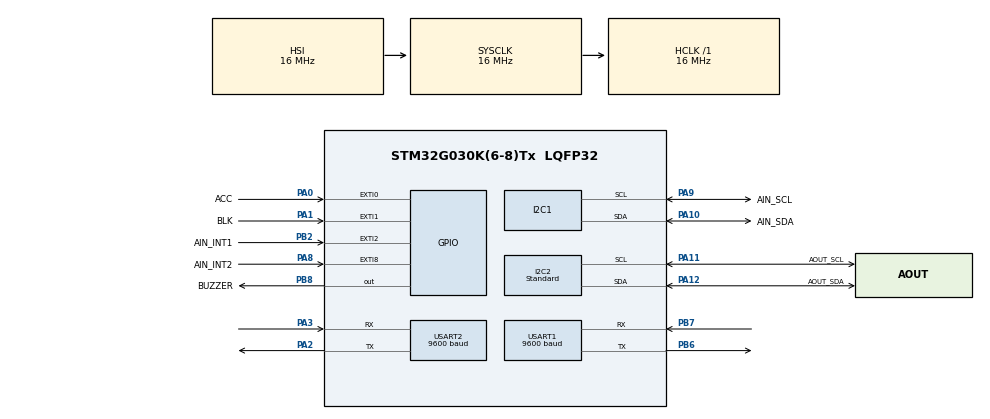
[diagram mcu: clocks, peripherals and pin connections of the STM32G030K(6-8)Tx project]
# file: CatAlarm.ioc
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I2C1.Speed=100
I2C2.I2C_Speed_Mode=I2C_Standard
Mcu.Family=STM32G0
Mcu.Name=STM32G030K(6-8)Tx
Mcu.Package=LQFP32
NVIC.EXTI0_1_IRQn=true\:0\:0\:false\:false\:true\:true\:true\:true
NVIC.TIM3_IRQn=true\:0\:0\:false\:false\:true\:true\:true\:true
PA0.GPIO_Label=ACC
PA0.GPIO_ModeDefaultEXTI=GPIO_MODE_IT_RISING_FALLING
PA0.Signal=GPXTI0
PA1.GPIO_Label=BLK
PA1.GPIO_ModeDefaultEXTI=GPIO_MODE_IT_RISING_FALLING
PA1.Signal=GPXTI1
PA10.GPIO_Label=AIN_SDA
PA10.Mode=I2C
PA10.Signal=I2C1_SDA
PA11\ [PA9].GPIO_Label=AOUT_SCL
PA11\ [PA9].Mode=I2C
PA11\ [PA9].Signal=I2C2_SCL
PA12\ [PA10].GPIO_Label=AOUT_SDA
PA12\ [PA10].Mode=I2C
PA12\ [PA10].Signal=I2C2_SDA
PA13.Mode=Serial_Wire
PA13.Signal=SYS_SWDIO
PA14-BOOT0.Mode=Serial_Wire
PA14-BOOT0.Signal=SYS_SWCLK
PA2.Mode=Asynchronous
PA2.Signal=USART2_TX
PA3.Mode=Asynchronous
PA3.Signal=USART2_RX
PA8.GPIO_Label=AIN_INT2
PA8.Signal=GPXTI8
PA9.GPIO_Label=AIN_SCL
PA9.Mode=I2C
PA9.Signal=I2C1_SCL
PB2.GPIO_Label=AIN_INT1
PB2.Signal=GPXTI2
PB6.Mode=Asynchronous
PB6.Signal=USART1_TX
PB7.Mode=Asynchronous
PB7.Signal=USART1_RX
PB8.GPIO_Label=BUZZER
PB8.Signal=GPIO_Output
ProjectManager.HeapSize=0x200
ProjectManager.StackSize=0x400
ProjectManager.TargetToolchain=STM32CubeIDE
RCC.ADCFreq_Value=16000000
RCC.AHBFreq_Value=16000000
RCC.CortexFreq_Value=16000000
RCC.EXTERNAL_CLOCK_VALUE=12288000
RCC.HCLKFreq_Value=16000000
RCC.HSE_VALUE=8000000
RCC.HSI_VALUE=16000000
RCC.LSE_VALUE=32768
RCC.SYSCLKFreq_VALUE=16000000
RCC.VCOOutputFreq_Value=128000000
TIM3.Period=39999
TIM3.Prescaler=3
USART1.BaudRate=9600
USART1.VirtualMode-Asynchronous=VM_ASYNC
USART2.BaudRate=9600
USART2.VirtualMode-Asynchronous=VM_ASYNC
VP_RTC_VS_RTC_Activate.Mode=RTC_Enabled
VP_RTC_VS_RTC_Calendar.Mode=RTC_Calendar
VP_TIM3_VS_ClockSourceINT.Mode=Internal
board=custom

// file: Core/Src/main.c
/* USER CODE BEGIN Header */
/**
  ******************************************************************************
  * @file           : main.c
  * @brief          : Main program body
  ******************************************************************************
  * @attention
  *
  * Copyright (c) 2024 STMicroelectronics.
  * All rights reserved.
  *
  * This software is licensed under terms that can be found in the LICENSE file
  * in the root directory of this software component.
  * If no LICENSE file comes with this software, it is provided AS-IS.
  *
  ******************************************************************************
  */
/* USER CODE END Header */
#include "main.h"
#include "i2c.h"
#include "rtc.h"
#include "tim.h"
#include "usart.h"
#include "gpio.h"

void SystemClock_Config(void);

int main(void)
{

  /* MCU Configuration--------------------------------------------------------*/

  /* Reset of all peripherals, Initializes the Flash interface and the Systick. */
  HAL_Init();

  /* Configure the system clock */
  SystemClock_Config();

  /* Initialize all configured peripherals */
  MX_GPIO_Init();
  MX_I2C1_Init();
  MX_USART1_UART_Init();
  MX_USART2_UART_Init();
  MX_I2C2_Init();
  MX_TIM3_Init();
  MX_RTC_Init();

  /* Infinite loop */
  /* USER CODE BEGIN WHILE */
  //lis2dw12_init2();
  //lis2dw12_wake_up();

  alt_main();

  //testwho_status = HAL_I2C_Mem_Read(&hi2c2, LIS2DW12_I2C_ADD_L, LIS2DW12_WHO_AM_I, I2C_MEMADD_SIZE_8BIT, &testwho, 1, 100);
  while (1)
  {

    /* USER CODE END WHILE */

  }
}

void SystemClock_Config(void)
{
  RCC_OscInitTypeDef RCC_OscInitStruct = {0};
  RCC_ClkInitTypeDef RCC_ClkInitStruct = {0};

  /** Configure the main internal regulator output voltage
  */
  HAL_PWREx_ControlVoltageScaling(PWR_REGULATOR_VOLTAGE_SCALE1);

  /** Initializes the RCC Oscillators according to the specified parameters
  * in the RCC_OscInitTypeDef structure.
  */
  RCC_OscInitStruct.OscillatorType = RCC_OSCILLATORTYPE_HSI|RCC_OSCILLATORTYPE_LSI;
  RCC_OscInitStruct.HSIState = RCC_HSI_ON;
  RCC_OscInitStruct.HSIDiv = RCC_HSI_DIV1;
  RCC_OscInitStruct.HSICalibrationValue = RCC_HSICALIBRATION_DEFAULT;
  RCC_OscInitStruct.LSIState = RCC_LSI_ON;
  RCC_OscInitStruct.PLL.PLLState = RCC_PLL_NONE;
  if (HAL_RCC_OscConfig(&RCC_OscInitStruct) != HAL_OK)
  {
    Error_Handler();
  }

  /** Initializes the CPU, AHB and APB buses clocks
  */
  RCC_ClkInitStruct.ClockType = RCC_CLOCKTYPE_HCLK|RCC_CLOCKTYPE_SYSCLK
                              |RCC_CLOCKTYPE_PCLK1;
  RCC_ClkInitStruct.SYSCLKSource = RCC_SYSCLKSOURCE_HSI;
  RCC_ClkInitStruct.AHBCLKDivider = RCC_SYSCLK_DIV1;
  RCC_ClkInitStruct.APB1CLKDivider = RCC_HCLK_DIV1;

  if (HAL_RCC_ClockConfig(&RCC_ClkInitStruct, FLASH_LATENCY_0) != HAL_OK)
  {
    Error_Handler();
  }
}

void Error_Handler(void)
{
  __disable_irq();
  while (1)
  {
  }
}
